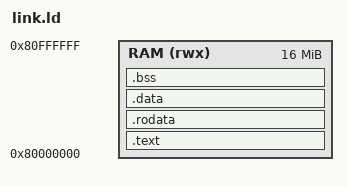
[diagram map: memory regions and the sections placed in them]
ENTRY(_start)
MEMORY { RAM (rwx) : ORIGIN = 0x80000000, LENGTH = 16M }
SECTIONS {
    .text : { *(.text.start) *(.text*) } > RAM
    .rodata : { *(.rodata*) *(.srodata*) } > RAM
    .data : { *(.data*) *(.sdata*) } > RAM
    .bss (NOLOAD) : {
        . = ALIGN(4); __bss_start = .;
        *(.bss*) *(.sbss*) *(COMMON)
        . = ALIGN(4); __bss_end = .;
    } > RAM
    __stack_top = ORIGIN(RAM) + LENGTH(RAM);
    ASSERT(__bss_end + 65536 < __stack_top, "insufficient stack")
}
